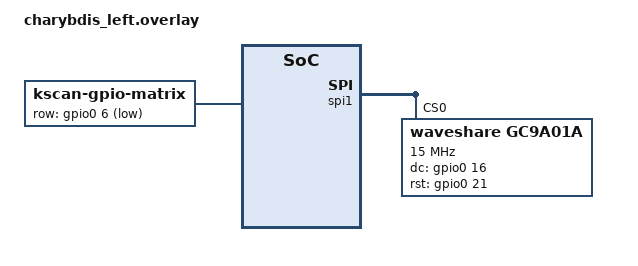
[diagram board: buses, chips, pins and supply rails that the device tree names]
/*
 * GC9A01A SPI Display overlay for Pinnacle 100
 */

#include "charybdis.dtsi"

/ {
    kscan0: kscan {
        compatible = "zmk,kscan-gpio-matrix";
        label = "KSCAN";
        row-gpios = <&gpio0 6 (GPIO_ACTIVE_LOW | GPIO_PULL_UP)>;
    };
};

&spi1 {
    status = "okay";
    
    gc9a01a: gc9a01a@0 {
        compatible = "waveshare,gc9a01a";
        reg = <0>;
        spi-max-frequency = <15000000>;
        dc-gpios = <&gpio0 16 GPIO_ACTIVE_HIGH>;
        rst-gpios = <&gpio0 21 GPIO_ACTIVE_HIGH>;
        status = "okay";
    };
};
